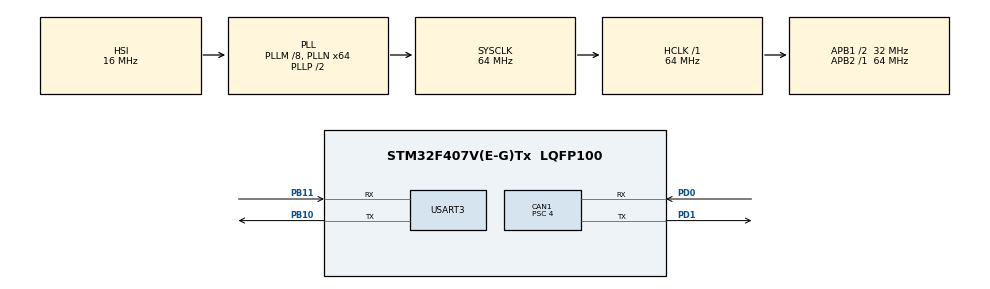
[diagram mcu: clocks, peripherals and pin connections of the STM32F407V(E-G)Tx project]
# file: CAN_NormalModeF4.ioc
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CAN1.ABOM=DISABLE
CAN1.AWUM=DISABLE
CAN1.BS1=CAN_BS1_12TQ
CAN1.BS2=CAN_BS2_3TQ
CAN1.CalculateBaudRate=500000
CAN1.CalculateTimeBit=2000
CAN1.CalculateTimeQuantum=125.0
CAN1.NART=ENABLE
CAN1.Prescaler=4
CAN1.SJW=CAN_SJW_2TQ
Mcu.Family=STM32F4
Mcu.Name=STM32F407V(E-G)Tx
Mcu.Package=LQFP100
NVIC.CAN1_RX0_IRQn=true\:0\:0\:false\:false\:true\:true\:true\:true
NVIC.PriorityGroup=NVIC_PRIORITYGROUP_4
PB10.Mode=Asynchronous
PB10.Signal=USART3_TX
PB11.Mode=Asynchronous
PB11.Signal=USART3_RX
PD0.GPIO_PuPd=GPIO_PULLUP
PD0.Mode=CAN_Activate
PD0.Signal=CAN1_RX
PD1.Mode=CAN_Activate
PD1.Signal=CAN1_TX
ProjectManager.HeapSize=0x200
ProjectManager.StackSize=0x400
ProjectManager.TargetToolchain=STM32CubeIDE
RCC.48MHZClocksFreq_Value=32000000
RCC.AHBFreq_Value=64000000
RCC.APB1CLKDivider=RCC_HCLK_DIV2
RCC.APB1Freq_Value=32000000
RCC.APB1TimFreq_Value=64000000
RCC.APB2Freq_Value=64000000
RCC.APB2TimFreq_Value=64000000
RCC.CortexFreq_Value=64000000
RCC.HCLKFreq_Value=64000000
RCC.HSE_VALUE=25000000
RCC.HSI_VALUE=16000000
RCC.LSE_VALUE=32768
RCC.PLLM=8
RCC.PLLN=64
RCC.SYSCLKFreq_VALUE=64000000
RCC.SYSCLKSource=RCC_SYSCLKSOURCE_PLLCLK
RCC.VCOOutputFreq_Value=128000000
USART3.VirtualMode=VM_ASYNC
VP_TIM6_VS_ClockSourceINT.Mode=Enable_Timer
board=custom

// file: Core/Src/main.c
/* USER CODE BEGIN Header */
/**
 ******************************************************************************
 * @file           : main.c
 * @brief          : Main program body
 ******************************************************************************
 * @attention
 *
 * Copyright (c) 2026 STMicroelectronics.
 * All rights reserved.
 *
 * This software is licensed under terms that can be found in the LICENSE file
 * in the root directory of this software component.
 * If no LICENSE file comes with this software, it is provided AS-IS.
 *
 ******************************************************************************
 */
/* USER CODE END Header */
#include "main.h"
#include "can.h"
#include "tim.h"
#include "usart.h"
#include "gpio.h"

/* USER CODE BEGIN Includes */
#include <string.h>
#include <stdio.h>
#include "rtos.h"
#include "CanTp.h"
/* USER CODE END Includes */

void SystemClock_Config(void);

int main(void)
{

  /* MCU Configuration--------------------------------------------------------*/

  /* Reset of all peripherals, Initializes the Flash interface and the Systick. */
  HAL_Init();

  /* Configure the system clock */
  SystemClock_Config();

  /* Initialize all configured peripherals */
  MX_GPIO_Init();
  MX_CAN1_Init();
  MX_TIM6_Init();
  MX_USART3_UART_Init();
  /* USER CODE BEGIN 2 */
  UART_Send("UART Initialized Successfully!\r\n");
  /* Initialize the transport before its first 10 ms activation. */
  CanTp_Init();
  App_RtosStart();
  /* USER CODE END 2 */

  /* Infinite loop */
  while (1)
  {

    /* USER CODE BEGIN 3 */
    Error_Handler();
  }
  /* USER CODE END 3 */
}

void SystemClock_Config(void)
{
  RCC_OscInitTypeDef RCC_OscInitStruct = {0};
  RCC_ClkInitTypeDef RCC_ClkInitStruct = {0};

  /** Configure the main internal regulator output voltage
  */
  __HAL_RCC_PWR_CLK_ENABLE();
  __HAL_PWR_VOLTAGESCALING_CONFIG(PWR_REGULATOR_VOLTAGE_SCALE1);

  /** Initializes the RCC Oscillators according to the specified parameters
  * in the RCC_OscInitTypeDef structure.
  */
  RCC_OscInitStruct.OscillatorType = RCC_OSCILLATORTYPE_HSI;
  RCC_OscInitStruct.HSIState = RCC_HSI_ON;
  RCC_OscInitStruct.HSICalibrationValue = RCC_HSICALIBRATION_DEFAULT;
  RCC_OscInitStruct.PLL.PLLState = RCC_PLL_ON;
  RCC_OscInitStruct.PLL.PLLSource = RCC_PLLSOURCE_HSI;
  RCC_OscInitStruct.PLL.PLLM = 8;
  RCC_OscInitStruct.PLL.PLLN = 64;
  RCC_OscInitStruct.PLL.PLLP = RCC_PLLP_DIV2;
  RCC_OscInitStruct.PLL.PLLQ = 4;
  if (HAL_RCC_OscConfig(&RCC_OscInitStruct) != HAL_OK)
  {
    Error_Handler();
  }

  /** Initializes the CPU, AHB and APB buses clocks
  */
  RCC_ClkInitStruct.ClockType = RCC_CLOCKTYPE_HCLK|RCC_CLOCKTYPE_SYSCLK
                              |RCC_CLOCKTYPE_PCLK1|RCC_CLOCKTYPE_PCLK2;
  RCC_ClkInitStruct.SYSCLKSource = RCC_SYSCLKSOURCE_PLLCLK;
  RCC_ClkInitStruct.AHBCLKDivider = RCC_SYSCLK_DIV1;
  RCC_ClkInitStruct.APB1CLKDivider = RCC_HCLK_DIV2;
  RCC_ClkInitStruct.APB2CLKDivider = RCC_HCLK_DIV1;

  if (HAL_RCC_ClockConfig(&RCC_ClkInitStruct, FLASH_LATENCY_2) != HAL_OK)
  {
    Error_Handler();
  }
}

void Error_Handler(void)
{
  __disable_irq();
  while (1)
  {
  }
}
